AUTOSAR XML (schema 4-0-3)
package /ComponentTypes
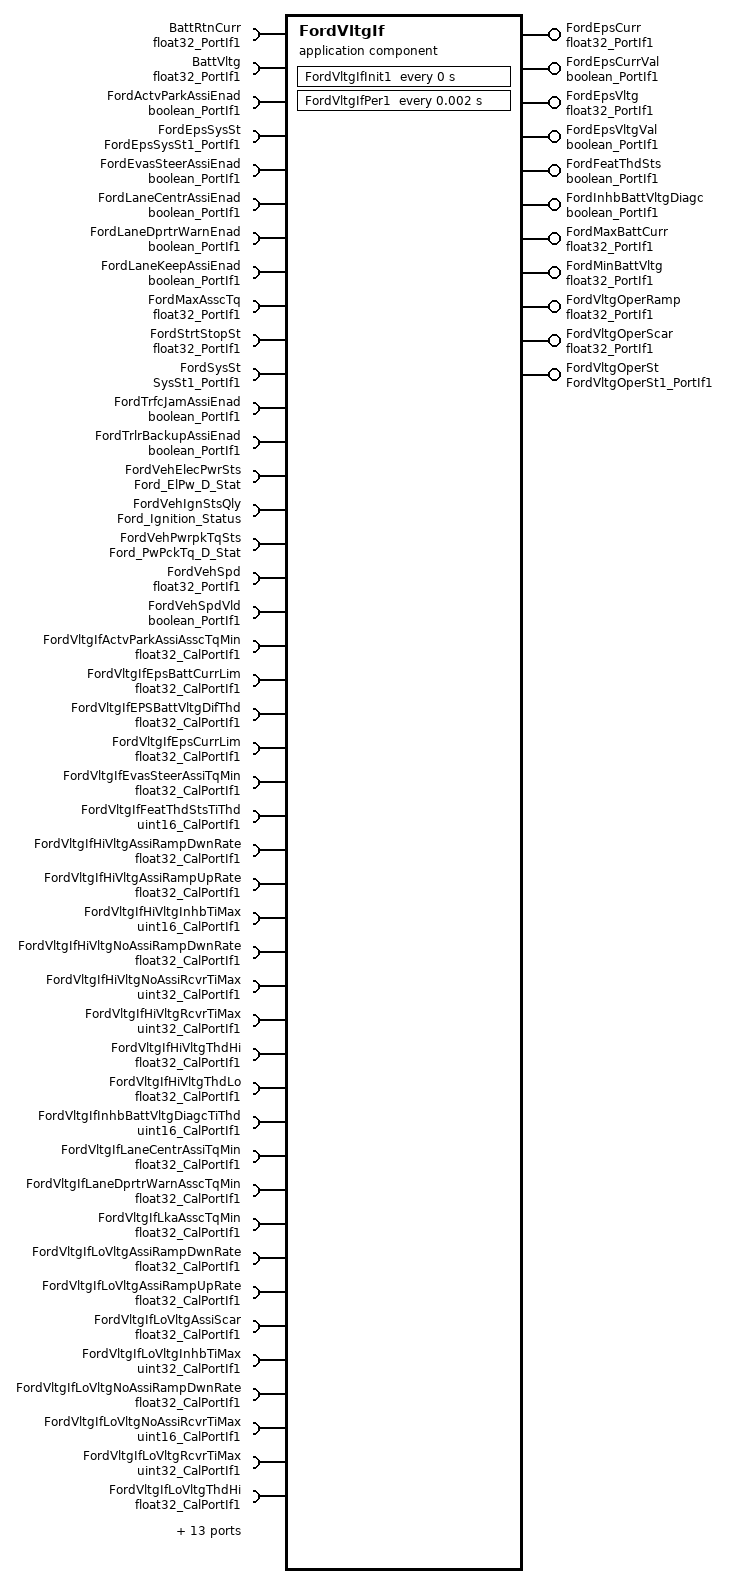
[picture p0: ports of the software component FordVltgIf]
  application sw component type FordVltgIf  # This function will inhibit battery voltage diagnostics, define primary voltage states and define transitions between battery voltage states
    11 x provide port:
      FordEpsCurr: nonqueued-sender-com-spec{data-element=Val, init-value=140.75}, provided-interface=float32_PortIf1  # Indicates the Ford EPS Current
      FordEpsCurrVal: nonqueued-sender-com-spec{data-element=Logl, init-value=0}, provided-interface=boolean_PortIf1
      FordEpsVltg: nonqueued-sender-com-spec{data-element=Val, init-value=18.75}, provided-interface=float32_PortIf1  # Indicates the Ford EPS Voltage
      FordEpsVltgVal: nonqueued-sender-com-spec{data-element=Logl, init-value=0}, provided-interface=boolean_PortIf1
      FordFeatThdSts: nonqueued-sender-com-spec{data-element=Logl, init-value=0}, provided-interface=boolean_PortIf1  # Indicates the Ford Feature Threshold Status
      FordInhbBattVltgDiagc: nonqueued-sender-com-spec{data-element=Logl, init-value=0}, provided-interface=boolean_PortIf1  # Indicates the Ford Inhibit Battery Voltage Diagnostic
      FordMaxBattCurr: nonqueued-sender-com-spec{data-element=Val, init-value=0}, provided-interface=float32_PortIf1  # Indicates the Maximum value of Ford Battery Current
      FordMinBattVltg: nonqueued-sender-com-spec{data-element=Val, init-value=0}, provided-interface=float32_PortIf1  # Indicates the Minimum value of Ford Battery Voltage
      FordVltgOperRamp: nonqueued-sender-com-spec{data-element=Val, init-value=50}, provided-interface=float32_PortIf1  # Indicates the Ford Voltage Operation Ramp
      FordVltgOperScar: nonqueued-sender-com-spec{data-element=Val, init-value=0}, provided-interface=float32_PortIf1  # Indicates the Ford Voltage Operation Scaler
      FordVltgOperSt: nonqueued-sender-com-spec{data-element=Val, init-value=0}, provided-interface=FordVltgOperSt1_PortIf1  # Indicates the Ford Voltage Operation State
    57 x require port:
      BattRtnCurr: nonqueued-receiver-com-spec{data-element=Val, filter=data-filter-type=ALWAYS, init-value=0}, required-interface=float32_PortIf1  # Indicates the Ford Battery Return Current
      BattVltg: nonqueued-receiver-com-spec{data-element=Val, filter=data-filter-type=ALWAYS, init-value=6}, required-interface=float32_PortIf1  # Indicates the Ford Battery Voltage
      FordActvParkAssiEnad: nonqueued-receiver-com-spec{data-element=Logl, filter=data-filter-type=ALWAYS, init-value=0}, required-interface=boolean_PortIf1  # Indicates the Ford Active Park Assist Enabled
      FordEpsSysSt: nonqueued-receiver-com-spec{data-element=Val, filter=data-filter-type=ALWAYS, init-value=0}, required-interface=FordEpsSysSt1_PortIf1  # Indicates the EPS System State
      FordEvasSteerAssiEnad: nonqueued-receiver-com-spec{data-element=Logl, filter=data-filter-type=ALWAYS, init-value=0}, required-interface=boolean_PortIf1  # Indicates the Ford Evasive Steering Assist Enabled
      FordLaneCentrAssiEnad: nonqueued-receiver-com-spec{data-element=Logl, filter=data-filter-type=ALWAYS, init-value=0}, required-interface=boolean_PortIf1  # Indicates the Ford Lane Centering Assist Enabled
      FordLaneDprtrWarnEnad: nonqueued-receiver-com-spec{data-element=Logl, filter=data-filter-type=ALWAYS, init-value=0}, required-interface=boolean_PortIf1  # Indicates the Ford Lane Departure Warning Enabled
      FordLaneKeepAssiEnad: nonqueued-receiver-com-spec{data-element=Logl, filter=data-filter-type=ALWAYS, init-value=0}, required-interface=boolean_PortIf1  # Indicates the Ford Lane Keep Assist Enabled
      FordMaxAsscTq: nonqueued-receiver-com-spec{data-element=Val, filter=data-filter-type=ALWAYS, init-value=0}, required-interface=float32_PortIf1  # Indicates the Ford Maximum Assistance Torque
      FordStrtStopSt: nonqueued-receiver-com-spec{data-element=Val, filter=data-filter-type=ALWAYS, init-value=0}, required-interface=float32_PortIf1
      FordSysSt: nonqueued-receiver-com-spec{data-element=Val, filter=data-filter-type=ALWAYS, init-value=3}, required-interface=SysSt1_PortIf1  # Indicates the System State
      FordTrfcJamAssiEnad: nonqueued-receiver-com-spec{data-element=Logl, filter=data-filter-type=ALWAYS, init-value=0}, required-interface=boolean_PortIf1  # Indicates the Ford Traffic Jam Assist Enabled
      FordTrlrBackupAssiEnad: nonqueued-receiver-com-spec{data-element=Logl, filter=data-filter-type=ALWAYS, init-value=0}, required-interface=boolean_PortIf1  # Indicates the Ford Trailer Backup Assistance Enabled
      FordVehElecPwrSts: nonqueued-receiver-com-spec{data-element=Ford_ElPw_D_Stat, filter=data-filter-type=ALWAYS, init-value=0}, required-interface=Ford_ElPw_D_Stat  # Indicates the Ford Electrical Power Status
      FordVehIgnStsQly: nonqueued-receiver-com-spec{data-element=Ford_Ignition_Status, filter=data-filter-type=ALWAYS, init-value=0}, required-interface=Ford_Ignition_Status  # Indicates the Ford Vehicle Ignition Status Quality
      FordVehPwrpkTqSts: nonqueued-receiver-com-spec{data-element=Ford_PwPckTq_D_Stat, filter=data-filter-type=ALWAYS, init-value=0}, required-interface=Ford_PwPckTq_D_Stat  # Indicates the Ford Vehicle Power-pack Torque Status
      FordVehSpd: nonqueued-receiver-com-spec{data-element=Val, filter=data-filter-type=ALWAYS, init-value=0}, required-interface=float32_PortIf1  # Indicates the Ford Vehicle Speed
      FordVehSpdVld: nonqueued-receiver-com-spec{data-element=Logl, filter=data-filter-type=ALWAYS, init-value=0}, required-interface=boolean_PortIf1  # Indicates the Ford Vehicle Speed Validity
      FordVltgIfActvParkAssiAsscTqMin: parameter-require-com-spec{init-value=0, parameter=Val}, required-interface=float32_CalPortIf1  # Indicates the Minimum of APA Assistance Torque
      FordVltgIfEpsBattCurrLim: parameter-require-com-spec{init-value=0, parameter=Val}, required-interface=float32_CalPortIf1  # Indicates the EPS Battery Current Limit
      FordVltgIfEPSBattVltgDifThd: parameter-require-com-spec{init-value=5, parameter=Val}, required-interface=float32_CalPortIf1
      FordVltgIfEpsCurrLim: parameter-require-com-spec{init-value=40, parameter=Val}, required-interface=float32_CalPortIf1  # Indicates the EPS Current Limit
      FordVltgIfEvasSteerAssiTqMin: parameter-require-com-spec{init-value=90, parameter=Val}, required-interface=float32_CalPortIf1  # Indicates the Minimum of ESA Assistance Torque
      FordVltgIfFeatThdStsTiThd: parameter-require-com-spec{init-value=1000, parameter=Val}, required-interface=uint16_CalPortIf1  # Indicates the Feature Threshold Status Threshold
      FordVltgIfHiVltgAssiRampDwnRate: parameter-require-com-spec{init-value=50, parameter=Val}, required-interface=float32_CalPortIf1  # Indicates the High Voltage Assist Ramp Down Rate
      FordVltgIfHiVltgAssiRampUpRate: parameter-require-com-spec{init-value=50, parameter=Val}, required-interface=float32_CalPortIf1  # Indicates the High Voltage Assist Ramp Up Rate
      FordVltgIfHiVltgInhbTiMax: parameter-require-com-spec{init-value=100, parameter=Val}, required-interface=uint16_CalPortIf1  # Indicates the Maximum value of High Voltage Inhibit Time
      FordVltgIfHiVltgNoAssiRampDwnRate: parameter-require-com-spec{init-value=50, parameter=Val}, required-interface=float32_CalPortIf1  # Indicates the High Voltage No Assist Ramp Down Rate
      FordVltgIfHiVltgNoAssiRcvrTiMax: parameter-require-com-spec{init-value=2000, parameter=Val}, required-interface=uint32_CalPortIf1  # Indicates the Maximum value of High Voltage No Assist Recover Time
      FordVltgIfHiVltgRcvrTiMax: parameter-require-com-spec{init-value=500, parameter=Val}, required-interface=uint32_CalPortIf1  # Indicates the Maximum of High Voltage Recover Time
      FordVltgIfHiVltgThdHi: parameter-require-com-spec{init-value=19, parameter=Val}, required-interface=float32_CalPortIf1  # Indicates the High Voltage Threshold High
      FordVltgIfHiVltgThdLo: parameter-require-com-spec{init-value=18, parameter=Val}, required-interface=float32_CalPortIf1  # Indicates the High Voltage Threshold Low
      FordVltgIfInhbBattVltgDiagcTiThd: parameter-require-com-spec{init-value=1000, parameter=Val}, required-interface=uint16_CalPortIf1  # Indicates the Inhibit Battery Voltage Diagnostic Threshold
      FordVltgIfLaneCentrAssiTqMin: parameter-require-com-spec{init-value=90, parameter=Val}, required-interface=float32_CalPortIf1  # Indicates the Minimum value of LCA Assistance Torque
      FordVltgIfLaneDprtrWarnAsscTqMin: parameter-require-com-spec{init-value=90, parameter=Val}, required-interface=float32_CalPortIf1  # Indicates the Minimum value of LDW Assistance Torque
      FordVltgIfLkaAsscTqMin: parameter-require-com-spec{init-value=90, parameter=Val}, required-interface=float32_CalPortIf1  # Indicates the Minimum value of LKA Assistance Torque
      FordVltgIfLoVltgAssiRampDwnRate: parameter-require-com-spec{init-value=50, parameter=Val}, required-interface=float32_CalPortIf1  # Indicates the Low Voltage Assist Ramp Down Rate
      FordVltgIfLoVltgAssiRampUpRate: parameter-require-com-spec{init-value=50, parameter=Val}, required-interface=float32_CalPortIf1  # Indicates the Low Voltage Assist Ramp Up Rate
      FordVltgIfLoVltgAssiScar: parameter-require-com-spec{init-value=0.4, parameter=Val}, required-interface=float32_CalPortIf1  # Indicates the Low Voltage Assist Scaler
      FordVltgIfLoVltgInhbTiMax: parameter-require-com-spec{init-value=100, parameter=Val}, required-interface=uint32_CalPortIf1  # Indicates the Maximum value of Low Voltage Inhibit
      FordVltgIfLoVltgNoAssiRampDwnRate: parameter-require-com-spec{init-value=50, parameter=Val}, required-interface=float32_CalPortIf1  # Indicates the Low Voltage No Assist Ramp Down Rate
      FordVltgIfLoVltgNoAssiRcvrTiMax: parameter-require-com-spec{init-value=2000, parameter=Val}, required-interface=uint16_CalPortIf1  # Indicates the Low Voltage No Assist Recover Maximum Time
      FordVltgIfLoVltgRcvrTiMax: parameter-require-com-spec{init-value=500, parameter=Val}, required-interface=uint32_CalPortIf1  # Indicates the Low Voltage Recover Maximum
      FordVltgIfLoVltgThdHi: parameter-require-com-spec{init-value=11, parameter=Val}, required-interface=float32_CalPortIf1  # Indicates the Low Voltage Threshold High
      FordVltgIfLoVltgThdLo: parameter-require-com-spec{init-value=7, parameter=Val}, required-interface=float32_CalPortIf1  # Indicates the Low Voltage Threshold Low
      FordVltgIfLoVltgThdMid: parameter-require-com-spec{init-value=10, parameter=Val}, required-interface=float32_CalPortIf1  # Indicates the Low Voltage Threshold Middle
      FordVltgIfLoVltgThdMidToLoTiMax: parameter-require-com-spec{init-value=1000, parameter=Val}, required-interface=uint32_CalPortIf1  # Indicates the Low Voltage Threshold Middle To Low Maximum Time
      FordVltgIfLoVltgTqScaDwnRate: parameter-require-com-spec{init-value=50, parameter=Val}, required-interface=float32_CalPortIf1  # Indicates the Low Voltage Torque Scale Down Rate
      FordVltgIfLoVltgTqScagFac: parameter-require-com-spec{init-value=0.25, parameter=Val}, required-interface=float32_CalPortIf1  # Indicates the Low Voltage Torque Scaling Factor
      FordVltgIfLoVltgTqScaUpRate: parameter-require-com-spec{init-value=50, parameter=Val}, required-interface=float32_CalPortIf1  # Indicates the Low Voltage Torque Scale Up Rate
      FordVltgIfTrfcJamAsscTqMin: parameter-require-com-spec{init-value=90, parameter=Val}, required-interface=float32_CalPortIf1  # Indicates the Traffic Jam Assistance Torque Minimum
      FordVltgIfTrlrBackupAssiTqMin: parameter-require-com-spec{init-value=90, parameter=Val}, required-interface=float32_CalPortIf1  # Indicates the Minimum value of TBA Assistance Torque
      FordVltgIfVehBattCircR: parameter-require-com-spec{init-value=0.1, parameter=Val}, required-interface=float32_CalPortIf1  # Indicates the Vehicle Battery Circuit Resistance
      GetRefTmr100MicroSec32bit: client-com-spec=Oper, required-interface=GetRefTmr100MicroSec32bit_PortIf1  # It captures simulation time fromthe SimnTi value obtained at root layer of model and gives the RefTmr
      GetSigImcData_f32: client-com-spec=Oper, required-interface=GetSigImcData_f32_PortIf1
      GetTiSpan100MicroSec32bit: client-com-spec=Oper, required-interface=GetTiSpan100MicroSec32bit_PortIf1  # It captures simulation time fromSimnTi value, handles counter wrapping, and subtracts RefTmr, provides the TiSpan
      SetNtcSts: client-com-spec=Oper, required-interface=SetNtcSts_PortIf1  # Set the NTC status
    behavior FordVltgIf_InternalBehavior
      ar-typed-per-instance-memorys:
        24 x data, all with sw-calibration-access=READ-ONLY:
          FeatThdStsRefTi: type=uint32  # For Software to keep track of Feature Threshold Status Reference Time
          HiToLoChk: type=uint8  # For Software to keep track of High To Low Check
          HiToMidChk: type=uint8  # For Software to keep track of High To Middle Check
          HiVltgInhbRefTi: type=uint32  # For Software to keep track of High Voltage Inhibit Reference Time
          HiVltgNoAssiRcvrRefTi: type=uint32  # For Software to keep track of High Voltage No Assist Recover Reference Time
          HiVltgRcvrRefTi: type=uint32  # For Software to keep track of High Voltage Recover Reference Time
          HiVltgRcvrTiMaxRefTi: type=uint32  # For Software to keep track of High Voltage Recover Time Maximum Reference Time
          InhbBattVltgDiagcRefTi: type=uint32  # For Software to keep track of Inhibit Battery Voltage Diagnostic Reference Time
          LoToHiChk: type=uint8  # For Software to keep track of Low To High Check
          LoToMidChk: type=uint8  # For Software to keep track of Low To Middle Check
          LoVltgInhbRefTi{1..3}: type=uint32  # For Software to keep track of Low Voltage Inhibit Reference Time {1..3}
          LoVltgNoAssiRcvrRefTi: type=uint32  # For Software to keep track of Low Voltage No Assist Recover Reference Time
          LoVltgRcvrRefTi: type=uint32  # For Software to keep track of Low Voltage Recover Reference Time
          LoVltgRcvrTiMaxRefTi: type=uint32  # For Software to keep track of Low Voltage Recover Time Maximum Reference Time
          LoVltgThdMidToLoRefTi: type=uint32  # For Software to keep track of Low Voltage Threshold Middle To Low Reference Time
          LoVltgThdMidToLoRefTmr: type=uint32  # For Software to keep track of Low Voltage Threshold Middle To Low Reference Timer
          MaxEpsBattCurrPrev: type=float32  # For Software to keep track of Maximum EPS Battery Current Previous
          MidToHiChk: type=uint8  # For Software to keep track of Middle To High Check
          MidToLoChk: type=uint8  # For Software to keep track of Middle To Low Check
          MinBattVltgPrev: type=float32  # For Software to keep track of Minimum Battery Voltage Previous
          PrevVltgOperRamp: type=float32  # For Software to keep track of Previous Voltage Operation Ramp
          PrevVltgOperScar: type=float32  # For Software to keep track of Previous Voltage Operation Scaler
      timing event FordVltgIf_InitEvent: start-on-event=FordVltgIfInit1, period=0
      timing event TMT_FordVltgIfPer1: start-on-event=FordVltgIfPer1, period=0.002
      port-api-options:
        enable-take-address=false, indirect-api=false, port=FordActvParkAssiEnad
        enable-take-address=false, indirect-api=false, port=FordEpsCurr
        enable-take-address=false, indirect-api=false, port=FordEpsCurrVal
        enable-take-address=false, indirect-api=false, port=FordEpsVltg
        enable-take-address=false, indirect-api=false, port=FordEpsVltgVal
        enable-take-address=false, indirect-api=false, port=FordEvasSteerAssiEnad
        enable-take-address=false, indirect-api=false, port=FordFeatThdSts
        enable-take-address=false, indirect-api=false, port=FordLaneCentrAssiEnad
        enable-take-address=false, indirect-api=false, port=FordLaneDprtrWarnEnad
        enable-take-address=false, indirect-api=false, port=FordLaneKeepAssiEnad
        enable-take-address=false, indirect-api=false, port=FordMaxBattCurr
        enable-take-address=false, indirect-api=false, port=FordStrtStopSt
        enable-take-address=false, indirect-api=false, port=FordSysSt
        enable-take-address=false, indirect-api=false, port=FordTrfcJamAssiEnad
        enable-take-address=false, indirect-api=false, port=FordTrlrBackupAssiEnad
        enable-take-address=false, indirect-api=false, port=FordVehElecPwrSts
        enable-take-address=false, indirect-api=false, port=FordVehIgnStsQly
        enable-take-address=false, indirect-api=false, port=FordVehPwrpkTqSts
        enable-take-address=false, indirect-api=false, port=FordVehSpd
        enable-take-address=false, indirect-api=false, port=FordVehSpdVld
        enable-take-address=false, indirect-api=false, port=FordVltgIfActvParkAssiAsscTqMin
        enable-take-address=false, indirect-api=false, port=FordVltgIfEpsBattCurrLim
        enable-take-address=false, indirect-api=false, port=FordVltgIfEPSBattVltgDifThd
        enable-take-address=false, indirect-api=false, port=FordVltgIfEpsCurrLim
        enable-take-address=false, indirect-api=false, port=FordVltgIfEvasSteerAssiTqMin
        enable-take-address=false, indirect-api=false, port=FordVltgIfFeatThdStsTiThd
        enable-take-address=false, indirect-api=false, port=FordVltgIfHiVltgAssiRampDwnRate
        enable-take-address=false, indirect-api=false, port=FordVltgIfHiVltgAssiRampUpRate
        enable-take-address=false, indirect-api=false, port=FordVltgIfHiVltgInhbTiMax
        enable-take-address=false, indirect-api=false, port=FordVltgIfHiVltgNoAssiRampDwnRate
        enable-take-address=false, indirect-api=false, port=FordVltgIfHiVltgNoAssiRcvrTiMax
        enable-take-address=false, indirect-api=false, port=FordVltgIfHiVltgRcvrTiMax
        enable-take-address=false, indirect-api=false, port=FordVltgIfHiVltgThdHi
        enable-take-address=false, indirect-api=false, port=FordVltgIfHiVltgThdLo
        enable-take-address=false, indirect-api=false, port=FordVltgIfInhbBattVltgDiagcTiThd
        enable-take-address=false, indirect-api=false, port=FordVltgIfLaneCentrAssiTqMin
        enable-take-address=false, indirect-api=false, port=FordVltgIfLaneDprtrWarnAsscTqMin
        enable-take-address=false, indirect-api=false, port=FordVltgIfLkaAsscTqMin
        enable-take-address=false, indirect-api=false, port=FordVltgIfLoVltgAssiRampDwnRate
        enable-take-address=false, indirect-api=false, port=FordVltgIfLoVltgAssiRampUpRate
        enable-take-address=false, indirect-api=false, port=FordVltgIfLoVltgAssiScar
        enable-take-address=false, indirect-api=false, port=FordVltgIfLoVltgInhbTiMax
        enable-take-address=false, indirect-api=false, port=FordVltgIfLoVltgNoAssiRampDwnRate
        enable-take-address=false, indirect-api=false, port=FordVltgIfLoVltgNoAssiRcvrTiMax
        enable-take-address=false, indirect-api=false, port=FordVltgIfLoVltgRcvrTiMax
        enable-take-address=false, indirect-api=false, port=FordVltgIfLoVltgThdHi
        enable-take-address=false, indirect-api=false, port=FordVltgIfLoVltgThdLo
        enable-take-address=false, indirect-api=false, port=FordVltgIfLoVltgThdMid
        enable-take-address=false, indirect-api=false, port=FordVltgIfLoVltgThdMidToLoTiMax
        enable-take-address=false, indirect-api=false, port=FordVltgIfLoVltgTqScaDwnRate
        enable-take-address=false, indirect-api=false, port=FordVltgIfLoVltgTqScagFac
        enable-take-address=false, indirect-api=false, port=FordVltgIfLoVltgTqScaUpRate
        enable-take-address=false, indirect-api=false, port=FordVltgIfTrfcJamAsscTqMin
        enable-take-address=false, indirect-api=false, port=FordVltgIfTrlrBackupAssiTqMin
        enable-take-address=false, indirect-api=false, port=FordVltgIfVehBattCircR
        enable-take-address=false, indirect-api=false, port=FordVltgOperRamp
        enable-take-address=false, indirect-api=false, port=FordVltgOperScar
        enable-take-address=false, indirect-api=false, port=FordVltgOperSt
        enable-take-address=false, indirect-api=false, port=GetRefTmr100MicroSec32bit
        enable-take-address=false, indirect-api=false, port=GetSigImcData_f32
        enable-take-address=false, indirect-api=false, port=GetTiSpan100MicroSec32bit
        enable-take-address=false, indirect-api=false, port=SetNtcSts
      runnable FordVltgIfInit1  # Initialization Runnable
        sync call SC_GetRefTmr100MicroSec32bit_Oper: operation=GetRefTmr100MicroSec32bit.Oper, timeout=0
        sync call SC_SetNtcSts_Oper: operation=SetNtcSts.Oper, timeout=0
      runnable FordVltgIfPer1  # Periodic Runnable at 2ms
        data-receive-point-by-arguments:
          18 x access:
            REC_BattRtnCurr_Val: accessed-variable=BattRtnCurr.Val
            REC_BattVltg_Val: accessed-variable=BattVltg.Val
            REC_FordActvParkAssiEnad_Logl: accessed-variable=FordActvParkAssiEnad.Logl
            REC_FordEpsSysSt_Val: accessed-variable=FordEpsSysSt.Val
            REC_FordEvasSteerAssiEnad_Logl: accessed-variable=FordEvasSteerAssiEnad.Logl
            REC_FordLaneCentrAssiEnad_Logl: accessed-variable=FordLaneCentrAssiEnad.Logl
            REC_FordLaneDprtrWarnEnad_Logl: accessed-variable=FordLaneDprtrWarnEnad.Logl
            REC_FordLaneKeepAssiEnad_Logl: accessed-variable=FordLaneKeepAssiEnad.Logl
            REC_FordMaxAsscTq_Val: accessed-variable=FordMaxAsscTq.Val
            REC_FordStrtStopSt_Val: accessed-variable=FordStrtStopSt.Val
            REC_FordSysSt_Val: accessed-variable=FordSysSt.Val
            REC_FordTrfcJamAssiEnad_Logl: accessed-variable=FordTrfcJamAssiEnad.Logl
            REC_FordTrlrBackupAssiEnad_Logl: accessed-variable=FordTrlrBackupAssiEnad.Logl
            REC_FordVehElecPwrSts_Ford_ElPw_D_Stat: accessed-variable=FordVehElecPwrSts.Ford_ElPw_D_Stat
            REC_FordVehIgnStsQly_Ford_Ignition_Status: accessed-variable=FordVehIgnStsQly.Ford_Ignition_Status
            REC_FordVehPwrpkTqSts_Ford_PwPckTq_D_Stat: accessed-variable=FordVehPwrpkTqSts.Ford_PwPckTq_D_Stat
            REC_FordVehSpd_Val: accessed-variable=FordVehSpd.Val
            REC_FordVehSpdVld_Logl: accessed-variable=FordVehSpdVld.Logl
        data-send-points:
          11 x access:
            SEND_FordEpsCurr_Val: accessed-variable=FordEpsCurr.Val
            SEND_FordEpsCurrVal_Logl: accessed-variable=FordEpsCurrVal.Logl
            SEND_FordEpsVltg_Val: accessed-variable=FordEpsVltg.Val
            SEND_FordEpsVltgVal_Logl: accessed-variable=FordEpsVltgVal.Logl
            SEND_FordFeatThdSts_Logl: accessed-variable=FordFeatThdSts.Logl
            SEND_FordInhbBattVltgDiagc_Logl: accessed-variable=FordInhbBattVltgDiagc.Logl
            SEND_FordMaxBattCurr_Val: accessed-variable=FordMaxBattCurr.Val
            SEND_FordMinBattVltg_Val: accessed-variable=FordMinBattVltg.Val
            SEND_FordVltgOperRamp_Val: accessed-variable=FordVltgOperRamp.Val
            SEND_FordVltgOperScar_Val: accessed-variable=FordVltgOperScar.Val
            SEND_FordVltgOperSt_Val: accessed-variable=FordVltgOperSt.Val
        4 x sync call, all with timeout=0:
          SC_GetRefTmr100MicroSec32bit_Oper: operation=GetRefTmr100MicroSec32bit.Oper
          SC_GetSigImcData_f32_Oper: operation=GetSigImcData_f32.Oper
          SC_GetTiSpan100MicroSec32bit_Oper: operation=GetTiSpan100MicroSec32bit.Oper
          SC_SetNtcSts_Oper: operation=SetNtcSts.Oper
  swc implementation FordVltgIf_Implementation: behavior=FordVltgIf_InternalBehavior
    code-descriptors:
      code Default: artifact-descriptors=autosar-engineering-object={short-label=Default, category=SWSRC}
